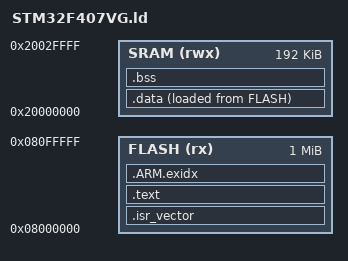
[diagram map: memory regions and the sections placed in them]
/* ============================================================================
 * @file STM32F407VG.ld
 * @brief STM32F407VG 链接脚本（Linker Script）
 *
 * 链接脚本是链接器（ld）的配置文件，告诉链接器：
 *   1. 目标平台的内存布局（Flash / SRAM 在哪，有多大）
 *   2. 编译产物（.text / .data / .bss 等）放到哪块内存
 *   3. 生成哪些特殊的运行时符号（供 C 代码引用）
 *
 * 【为什么要用链接脚本？】
 * 嵌入式系统的内存是固定的，不像 PC 有操作系统动态分配。
 * 我们必须告诉链接器："代码放 Flash，从 0x08000000 开始；数据放 SRAM，从 0x20000000 开始"。
 * 否则链接器会随机分配，导致程序无法运行。
 *
 * 【本项目关键配置】
 *   Flash：1MB @ 0x08000000（代码 + 常量 + .data 初始值）
 *   SRAM：192KB @ 0x20000000（运行时数据）
 *   栈：向下生长，顶在 SRAM 末端（0x20030000）
 *
 * 【学习要点】
 * - 理解 MEMORY 和 SECTIONS 的关系
 * - 理解 AT>FLASH 语法（初始值在 Flash，运行时在 SRAM）
 * - 理解 KEEP() 的作用（防止链接器删除向量表）
 * - 理解链接器生成的符号（_sidata / _sdata 等）供 C 代码使用
 *
 * 【参考】
 *   GNU LD 文档：https://sourceware.org/binutils/docs/ld/Scripts.html
 *   ARM linker script 入门：搜索 "ARM linker script tutorial"
 */

/* ============================================================================
 * SEARCH_DIR — 搜索路径
 * ============================================================================
 *
 * 告诉链接器在哪些目录里查找库文件（.a 静态库）。
 * arm-none-eabi-gcc 工具链把库安装在 /usr/arm-none-eabi/lib/ 等路径。
 * 这里列出的路径帮助链接器找到 newlib（标准C库）的实现。
 *
 * 实际使用中 -L 参数或 LIBRARY_PATH 环境变量也可以指定搜索路径。
 * SEARCH_DIR 在 GNU ld 中是旧式写法，现代做法是用 LDFLAGS -L 指定。*/

SEARCH_DIR("/usr/arm-none-eabi/newlib/thumb/v7e-m+fp/hard");
SEARCH_DIR("/usr/arm-none-eabi/lib");

/* ============================================================================
 * ENTRY — 程序入口点
 * ============================================================================
 *
 * ENTRY(symbol) 指定链接器的"入口"——即最终可执行文件的第一条指令的地址。
 * 这告诉链接器："从哪里开始放置代码"。
 *
 * 实际上 ARM 芯片的真正入口是由向量表决定的：
 *   芯片上电 → 从向量表 [0] 取 MSP → 从向量表 [1] 取 PC（跳转到 Reset_Handler）
 * 但链接器需要一个 ENTRY 符号来做一些内部计算（如扔掉无用的代码/数据）。
 *
 * 这里设为 Reset_Handler——链接器认为所有代码都应该从 Reset_Handler 能到达才算有用，
 *  unreachable 的函数会被 --gc-sections 删除。*/
ENTRY(Reset_Handler)

/* ============================================================================
 * _estack — 初始栈指针
 * ============================================================================
 *
 * _estack 是一个 C 代码可以访问的符号（main.c 里 extern 它）。
 * 但更重要的是：它同时也是链接器内部的符号，
 * 在向量表的 [0] 位置被引用（定义在 main.c 的 vectors[0]）。
 *
 * STM32F407VG SRAM = 192KB，起始于 0x20000000，结束于 0x20030000。
 * _estack = 0x20030000 = SRAM 结束地址 + 1 = 栈顶（C 语言的栈向下生长，所以栈顶在高端）。
 *
 * 为什么是 +1？
 * 因为地址 0x20030000 是"第一个不是 SRAM 的地址"（SRAM 范围是 [0x20000000, 0x20030000)）。
 * 栈从 0x2002FFF8 开始（假设 8 字节对齐），向下生长到 0x20000000 附近。
 * _estack 指向的位置是"栈可以使用的最顶端地址 + 1"，
 * 即 MSPLIM（Main Stack Pointer Limit）的一种实现方式。
 *
 * 【为什么不直接设为 0x20030000 - 8？】
 * 因为 ARM 的栈要求 8 字节或 16 字节对齐。
 * _estack 的值在向量表 [0] 被硬件（通过地址加载指令）使用，
 * 硬件会自动做对齐处理，所以直接给结束地址 +1 即可。*/
_estack = 0x20030000;  /* SRAM 192KB 结束地址 + 1 */

/* ============================================================================
 * MEMORY — 内存区域定义
 * ============================================================================
 *
 * MEMORY {} 块显式列出了目标平台的所有可用内存区域。
 * 链接器根据这里的信息分配各个 SECTION 到对应区域。
 *
 * 格式：
 *   name (attributes) : ORIGIN = start, LENGTH = size
 *
 * 属性（attributes）：
 *   r = read-only        （可读，如 Flash）
 *   w = read-write        （可读写，如 SRAM）
 *   x = executable        （可执行，CPU 能从这里取指）
 *   a = allocatable      （可分配，链接器可以把内容放这里）
 *
 * STM32F4 的 Flash 是 NOR Flash，可以直接寻址取指（不需要 DMA 或加载到 RAM），
 * 所以标记为 rx（可读 + 可执行）。
 *
 * SRAM 是易失性存储器，可以任意读写，标记为 rwx。*/

MEMORY
{
    /* ---------- Flash ----------
     * STM32F407VG 内置 1MB Flash，地址范围 0x08000000 ~ 0x080FFFFF（包含两端点）
     * 实际 0x08000000 ~ 0x080FFFFF 共 1,048,576 字节 = 1024KB = 1MB
     *
     * Flash 的用途（按链接顺序）：
     *   [0x08000000] 向量表（vectors）—— 必须放在最前面！
     *   [0x080000xx] .text（代码）
     *   [0x0800xxxx] .rodata（常量，const 全局变量）
     *   [0x0800xxxx] .data 初始值（AT>FLASH，实际存在 Flash）*/
    FLASH (rx) : ORIGIN = 0x08000000, LENGTH = 0x100000   /* 1MB = 1048576 bytes */

    /* ---------- SRAM ----------
     * STM32F407VG 内置 192KB SRAM，地址范围 0x20000000 ~ 0x2002FFFF
     *
     * SRAM 的用途：
     *   [0x20000000] .data 段（已初始化的全局/静态变量，运行时从 Flash 复制过来）
     *   [0x2000xxxx] .bss 段（未初始化的全局/静态变量，开机清零）
     *   [0x2000xxxx] Heap（动态内存，malloc 从这里分配）
     *   [0x2002xxxx] Stack（栈，向下生长）*/
    SRAM (rwx) : ORIGIN = 0x20000000, LENGTH = 0x30000    /* 192KB = 196608 bytes */
}

/* ============================================================================
 * SECTIONS — 段定义（最重要的部分）
 * ============================================================================
 *
 * SECTIONS {} 块定义了"段"（Section）的具体内容和放置规则。
 * "段"是链接器的最小分配单位——每个段内的所有数据会被连续放置。
 *
 * 常见的标准段：
 *   .text    — 机器码（函数体），CPU 执行的指令
 *   .rodata  — 只读数据（常量），如 const 变量、字符串字面量、跳转表
 *   .data    — 已初始化的全局/静态变量（初始值存储在 Flash，运行时复制到 SRAM）
 *   .bss     — 未初始化的全局/静态变量（运行时在 SRAM 中分配并清零）
 *   .ARM.exidx / .ARM.extab — ARM 异常处理表（用于 C++ 异常或 atexit）
 *
 * 【__attribute__((section(".name"))) 的作用】
 * C 代码里可以用 __attribute__((section(".my_data"))) 把变量/函数强制放到指定段。
 * 比如 main.c 里的 vectors 数组：
 *   void (* const vectors[])(void) __attribute__((section(".isr_vector")))
 * 强制把 vectors 放到 .isr_vector 段，链接脚本里用 KEEP(*(.isr_vector)) 保留它。*/

SECTIONS
{
    /* ========================================================================
     * .isr_vector — 中断向量表
     * ========================================================================
     *
     * 【为什么要单独一个段？】
     * 因为向量表必须放在 Flash 地址 0x08000000（硬件规定），
     * 而且必须原样保留（不能被链接器的垃圾回收删掉）。
     * 用单独的段，链接脚本可以用 KEEP() 显式保留。*/
    .isr_vector :
    {
        /* ALIGN(4) — 4 字节对齐
         * ARM 规定向量表地址必须 4 字节对齐（向量表每个 entry 是 4 字节）。
         * . = ALIGN(4) 把当前位置（.）对齐到 4 的倍数（如果没对齐就跳到下一个 4 的倍数）。*/
        . = ALIGN(4);

        /* _svector = . — 记录向量表起始地址
         * 链接器符号，可以在 C 代码里 extern 使用（虽然本项目没用到）。*/
        _svector = .;

        /* KEEP(*(.isr_vector))
         *
         * KEEP() 是关键：告诉链接器"不要删除这个段"（即使看起来没有被引用）。
         * --gc-sections 会删除所有"没有显式引用"的函数和数据。
         * 如果向量表数组没有被任何代码直接引用（它只通过硬件 PC 寄存器间接引用），
         * 链接器可能认为它是垃圾而删掉！
         * KEEP() 告诉链接器：这是给硬件用的，必须保留。*/
        KEEP(*(.isr_vector))

        /* 向量表结束后再次对齐，防止后续内容偏移错位 */
        . = ALIGN(4);
        _evector = .;
    } >FLASH   /* >FLASH 表示整个 .isr_vector 段放在 Flash 区域 */

    /* ========================================================================
     * .text — 代码段
     * ========================================================================
     *
     * .text 包含所有函数的机器码和常量数据（不包括 .rodata，虽然都属于只读）。
     * - .text 是可执行代码（CPU 取指从这里）
     * - .rodata 是只读数据（常量）
     *
     * 为什么分开？
     * - Flash 可以是只读的（XIP，eXecute In Place），CPU 直接从 Flash 取指
     * - 有些链接配置会把 .rodata 放到 RAM（需要改权限），或放到 Flash
     * - 分离后可以用不同的加载（load）和地址（address）配置
     *
     * *(.text) *(.text.*) 语法：
     *   * = 通配符，匹配任何目标文件
     *   (.text) = .text 段
     *   (.text.*) = .text.* 段（编译器可能生成 .text._Zxxx 这种子段）
     *   两者合并 = 所有 .text 相关段 */
    .text :
    {
        . = ALIGN(4);               /* 4 字节对齐（Thumb 指令要求）*/

        /* . = . 的含义：当前位置 . 被设置为 ...（记录当前地址）
         * _etext = . 记录 .text 段结束地址
         * 这个符号在 C 代码里 extern 用于 "copy .data from Flash to SRAM" */
        _etext = .;

        *(.text) *(.text.*)         /* 所有 .text 相关段 */
        *(.rodata) *(.rodata.*)     /* 所有 .rodata 相关段（常量）*/

        . = ALIGN(4);
    } >FLASH

    /* ========================================================================
     * .ARM.exidx — ARM 异常处理表
     * ========================================================================
     *
     * 用于 ARM 的异常处理（Exception Handling）机制。
     * 如果使用 C++ 异常或 atexit()，需要这个段。
     * 本项目不使用例外，把它也放 Flash 里，保留（KEEP 虽然没写，但 * 可以匹配到）。*/
    .ARM.exidx :
    {
        *(.ARM.exidx*) *(.gnu.linkonce.armexidx.*)
    } >FLASH

    /* ========================================================================
     * .data — 已初始化的全局/静态变量（运行时在 SRAM）
     * ========================================================================
     *
     * 这是嵌入式开发最重要的概念之一！
     *
     * 【问题背景】
     * 全局变量如 int counter = 5; 需要在程序启动时就拥有值"5"。
     * Flash 烧录文件（.bin/.hex）里存的是只读数据，可以掉电不丢失。
     * 但全局变量需要在 SRAM 里运行（因为程序运行时需要读写它们）。
     *
     * 【解决方案】AT>FLASH 语法
     * .data 段的"加载地址"（LMA，Load Memory Address）在 Flash，
     * 但"运行地址"（VMA，Virtual Memory Address）在 SRAM。
     *
     * 链接器自动生成 _sidata 符号 = .data 初始值在 Flash 的起始地址。
     * Reset_Handler 用 _sidata 从 Flash 读取初始值，复制到 SRAM 的 _sdata 地址。
     *
     * 【链接器生成的符号】
     *   _sdata：.data 段在 SRAM 的起始地址（运行时地址）
     *   _edata：.data 段在 SRAM 的结束地址（不含）
     * 这两个符号用于 Reset_Handler 的循环边界。*/
    .data :
    {
        . = ALIGN(4);               /* 4 字节对齐 */
        _sdata = .;                 /* 记录 .data 在 SRAM 的起始地址 */

        *(.data) *(.data.*)         /* 所有 .data 相关段 */

        . = ALIGN(4);
        _edata = .;                 /* 记录 .data 在 SRAM 的结束地址 */
    } >SRAM AT>FLASH
    /*   ↑           ↑
     * 运行地址       加载地址（初始值存储在 Flash，从这里复制到 SRAM）
     *
     * 效果：
     *   .text / .rodata / .isr_vector — 烧录时在 Flash，运行时也在 Flash（只读）
     *   .data — 烧录时在 Flash（初始值），运行时在 SRAM（可读写）*/

    /* ========================================================================
     * _sidata — .data 初始值在 Flash 中的地址
     * ========================================================================
     *
     * LOADADDR(.data) 是链接器内置函数，返回 .data 段的加载地址（即 AT>FLASH 指定的 Flash 地址）。
     * 这个符号在 C 代码里 extern，用于 Reset_Handler：
     *
     *   unsigned long *src  = &_sidata;  // Flash 地址（初始值来源）
     *   unsigned long *dest = &_sdata;   // SRAM 地址（目标位置）
     *   while (dest < &_edata) *dest++ = *src++;
     *
     * 注意：LOADADDR 是链接器脚本的内置变量，不是 C 变量。
     * 用 = 赋值后，链接器把它变成一个可被引用的符号。*/
    _sidata = LOADADDR(.data);

    /* ========================================================================
     * .bss — 未初始化的全局/静态变量（运行时在 SRAM）
     * ========================================================================
     *
     * 【为什么叫 BSS？】
     * BSS = Block Started by Symbol，由古老 IBM 汇编器术语沿用而来。
     *
     * 【重要特性】
     * .bss 段的特点：初始值全为 0！
     * 编译器不在烧录文件里存储 bss 的零值——只记录 bss 段的地址范围。
     * 运行时由 C 运行时库或 Reset_Handler 清零。
     * 这样可以节省大量 Flash 空间（bss 可能很大，但烧录文件里几乎不占空间）。
     *
     * 【链接器生成的符号】
     *   _sbss：bss 段起始地址（运行时在 SRAM）
     *   _ebss：bss 段结束地址
     * 用于 Reset_Handler 的清零循环。*/
    .bss :
    {
        . = ALIGN(4);
        _sbss = .;                  /* 记录 .bss 在 SRAM 的起始地址 */

        *(.bss) *(.bss.*)           /* 所有 .bss 相关段 */
        *(COMMON)                   /* COMMON 段：有些编译器把未初始化的全局变量放这里 */

        . = ALIGN(4);
        _ebss = .;                 /* 记录 .bss 在 SRAM 的结束地址 */
    } >SRAM
    /* 注意：.bss 没有 AT>FLASH！因为 bss 初始值全是 0，不需要从 Flash 加载 */

    /* ========================================================================
     * _end — 堆起始地址
     * ========================================================================
     *
     * _end 是一个非标准但广泛使用的符号，表示"程序结束后"的第一个地址。
     * 通常作为 malloc 的堆起始地址（堆从 _end 开始向上生长，栈从 _estack 向下生长）。
     *
     * 本项目不使用动态内存（无 malloc），所以 _end 仅作为信息符号。*/
    _end = .;

    /* ========================================================================
     * /DISCARD/ — 丢弃的段
     * ========================================================================
     *
     * libc.a（标准 C 库）和 libm.a（数学库）非常大，包含很多本项目不需要的函数。
     * --gc-sections 会自动删除未引用的函数，但这些库的一些特殊段可能不会被自动删除。
     * 这里显式丢弃它们，确保固件里不包含无用的 C 库代码。
     *
     * 如果之后需要使用 printf() / scanf() 等函数，需要移除这些丢弃规则，
     * 并添加 --whole-archive 等链接选项强制包含需要的库代码。*/
    /DISCARD/ :
    {
        libc.a (*)
        libm.a (*)
        libgcc.a (*)
    }
}
